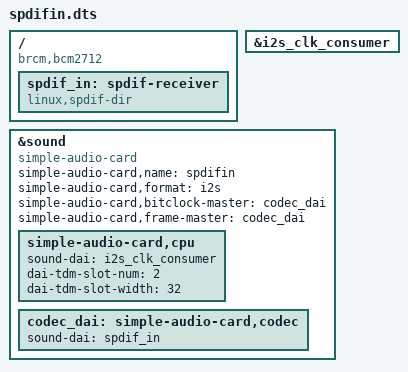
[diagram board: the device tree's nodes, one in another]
/dts-v1/;
/plugin/;
/ {
    compatible = "brcm,bcm2712";

    fragment@0 {
        target = <&i2s_clk_consumer>;
        __overlay__ { status = "okay"; };
    };

    fragment@1 {
        target-path = "/";
        __overlay__ {
            spdif_in: spdif-receiver {
                compatible = "linux,spdif-dir";
                #sound-dai-cells = <0>;
                status = "okay";
            };
        };
    };

    fragment@2 {
        target = <&sound>;
        __overlay__ {
            compatible = "simple-audio-card";
            simple-audio-card,name = "spdifin";
            status = "okay";
            simple-audio-card,format = "i2s";
            simple-audio-card,bitclock-master = <&codec_dai>;
            simple-audio-card,frame-master = <&codec_dai>;
            simple-audio-card,cpu {
                sound-dai = <&i2s_clk_consumer>;
                dai-tdm-slot-num = <2>;
                dai-tdm-slot-width = <32>;
            };
            codec_dai: simple-audio-card,codec {
                sound-dai = <&spdif_in>;
            };
        };
    };
};
